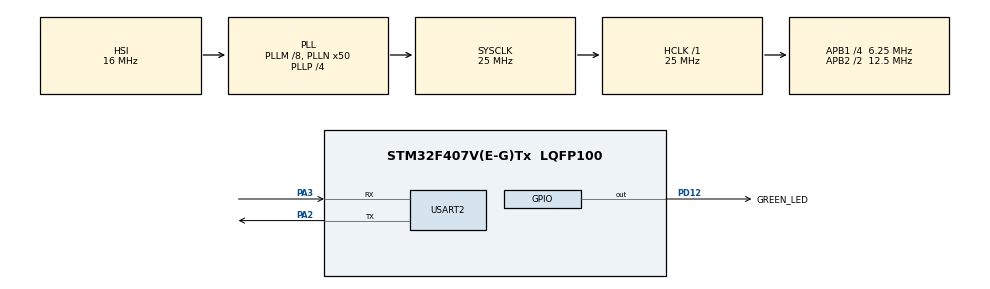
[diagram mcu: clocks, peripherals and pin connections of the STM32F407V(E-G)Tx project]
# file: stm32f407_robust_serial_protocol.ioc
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Mcu.Family=STM32F4
Mcu.Name=STM32F407V(E-G)Tx
Mcu.Package=LQFP100
NVIC.PriorityGroup=NVIC_PRIORITYGROUP_0
NVIC.USART2_IRQn=true\:0\:0\:false\:false\:true\:true\:true\:true
PA2.Mode=Asynchronous
PA2.Signal=USART2_TX
PA3.Mode=Asynchronous
PA3.Signal=USART2_RX
PD12.GPIO_Label=GREEN_LED
PD12.Signal=GPIO_Output
ProjectManager.HeapSize=0x200
ProjectManager.StackSize=0x400
ProjectManager.TargetToolchain=STM32CubeIDE
RCC.48MHZClocksFreq_Value=14285714.285714285
RCC.AHBFreq_Value=25000000
RCC.APB1CLKDivider=RCC_HCLK_DIV4
RCC.APB1Freq_Value=6250000
RCC.APB1TimFreq_Value=12500000
RCC.APB2CLKDivider=RCC_HCLK_DIV2
RCC.APB2Freq_Value=12500000
RCC.APB2TimFreq_Value=25000000
RCC.CortexFreq_Value=25000000
RCC.HCLKFreq_Value=25000000
RCC.HSE_VALUE=8000000
RCC.HSI_VALUE=16000000
RCC.LSE_VALUE=32768
RCC.PLLM=8
RCC.PLLN=50
RCC.PLLP=RCC_PLLP_DIV4
RCC.PLLQ=7
RCC.SYSCLKFreq_VALUE=25000000
RCC.SYSCLKSource=RCC_SYSCLKSOURCE_PLLCLK
RCC.VCOOutputFreq_Value=100000000
USART2.VirtualMode=VM_ASYNC
board=STM32F407G-DISC1

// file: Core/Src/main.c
/* USER CODE BEGIN Header */
/**
  ******************************************************************************
  * @file           : main.c
  * @brief          : Main program body
  ******************************************************************************
  * @attention
  *
  * Copyright (c) 2026 STMicroelectronics.
  * All rights reserved.
  *
  * This software is licensed under terms that can be found in the LICENSE file
  * in the root directory of this software component.
  * If no LICENSE file comes with this software, it is provided AS-IS.
  *
  ******************************************************************************
  */
/* USER CODE END Header */
#include "main.h"
#include "usart.h"
#include "gpio.h"

/* USER CODE BEGIN Includes */

#include <stdio.h>
#include <stdbool.h>
#include <string.h>
/* USER CODE END Includes */

/* USER CODE BEGIN PTD */

typedef enum
{
    PROTOCOL_CMD_PING          = 0x01U,
    PROTOCOL_CMD_GET_VERSION   = 0x02U,
    PROTOCOL_CMD_SET_LED       = 0x03U,
    PROTOCOL_CMD_GET_LED       = 0x04U,
    PROTOCOL_CMD_RESET_COUNTER = 0x05U
} ProtocolCommand_t;

typedef enum
{
    PROTOCOL_RESP_PONG          = 0x81U,
    PROTOCOL_RESP_VERSION       = 0x82U,
    PROTOCOL_RESP_LED_SET       = 0x83U,
    PROTOCOL_RESP_LED_STATE     = 0x84U,
    PROTOCOL_RESP_COUNTER_RESET = 0x85U,
    PROTOCOL_RESP_ERROR         = 0xFFU
} ProtocolResponse_t;

typedef enum
{
    PROTOCOL_ERROR_UNKNOWN_COMMAND = 0x01U,
    PROTOCOL_ERROR_INVALID_LENGTH  = 0x02U,
    PROTOCOL_ERROR_INVALID_PAYLOAD = 0x03U,
    PROTOCOL_ERROR_BAD_CHECKSUM    = 0x04U,
    PROTOCOL_ERROR_RX_TIMEOUT      = 0x05U,
    PROTOCOL_ERROR_BUFFER_OVERFLOW = 0x06U
} ProtocolError_t;

typedef enum
{
    PARSER_WAIT_START = 0,
    PARSER_READ_COMMAND,
    PARSER_READ_LENGTH,
    PARSER_READ_PAYLOAD,
    PARSER_READ_CHECKSUM
} ProtocolParserState_t;

typedef enum
{
    UART_RX_MODE_TEXT = 0,
    UART_RX_MODE_BINARY
} UartRxMode_t;

/* USER CODE END PTD */

/* USER CODE BEGIN PD */

#define RX_BUFFER_SIZE 				32U

#define PROTOCOL_START_BYTE        0xAAU
#define PROTOCOL_MAX_PAYLOAD_SIZE  16U

/* USER CODE END PD */

/* USER CODE BEGIN PV */

typedef struct
{
    uint8_t command;
    uint8_t length;
    uint8_t payload[PROTOCOL_MAX_PAYLOAD_SIZE];
    uint8_t checksum;
} ProtocolPacket_t;

static ProtocolPacket_t completed_packet;

static volatile bool completed_packet_ready = false;
static volatile bool bad_checksum_pending = false;

uint8_t uart_rx_byte;
uint8_t rx_buffer[RX_BUFFER_SIZE];

volatile uint8_t rx_index = 0U;
volatile uint8_t line_ready = 0U;
volatile uint8_t discard_until_newline = 0U;
volatile uint8_t rx_overflow = 0U;
volatile uint8_t rx_rearm_error = 0U;

static uint8_t green_led_state = 0U;

static ProtocolParserState_t parser_state = PARSER_WAIT_START;
static uint8_t parser_command = 0U;

static uint8_t parser_length = 0U;
static uint8_t parser_payload_index = 0U;

static uint8_t parser_payload[PROTOCOL_MAX_PAYLOAD_SIZE];

static uint8_t parser_received_checksum = 0U;
static uint8_t parser_calculated_checksum = 0U;

static bool parser_packet_complete = false;
static bool parser_packet_valid = false;

static volatile UartRxMode_t uart_rx_mode = UART_RX_MODE_TEXT;

/* USER CODE END PV */

void SystemClock_Config(void);
/* USER CODE BEGIN PFP */

static void uart_send_text(const char *text);
static void process_command(const char *command);

static uint8_t protocol_calculate_checksum(
    uint8_t command,
    uint8_t length,
    const uint8_t *payload
);

static bool protocol_checksum_self_test(void);

static void protocol_parser_reset(void);

static void protocol_parser_process_byte(uint8_t byte);

static bool protocol_parser_stage1_self_test(void);

static bool protocol_parser_stage2_self_test(void);

static bool protocol_parser_stage4_self_test(void);

static void protocol_publish_valid_packet(void);

static bool protocol_parser_stage5_self_test(void);

/* USER CODE END PFP */

/* USER CODE BEGIN 0 */

static void uart_send_text(const char *text)
{
    HAL_UART_Transmit(
        &huart2,
        (uint8_t *)text,
        strlen(text),
        HAL_MAX_DELAY
    );
}

static void process_command(const char *command)
{
    static const char set_led_prefix[] = "SET_LED ";
    const size_t set_led_prefix_length = sizeof(set_led_prefix) - 1U;

    if (strcmp(command, "PING") == 0)
    {
        uart_send_text("PONG\r\n");
    }
    else if (strcmp(command, "GET_VERSION") == 0)
    {
        uart_send_text("VERSION:1.0.0\r\n");
    }
    else if (strcmp(command, "GET_LED") == 0)
    {
        if (green_led_state == 1U)
        {
            uart_send_text("LED:1\r\n");
        }
        else
        {
            uart_send_text("LED:0\r\n");
        }
    }
    else if (strncmp(
                 command,
                 set_led_prefix,
                 set_led_prefix_length
             ) == 0)
    {
        const char *payload = command + set_led_prefix_length;

        if (strcmp(payload, "1") == 0)
        {
            HAL_GPIO_WritePin(
                GREEN_LED_GPIO_Port,
                GREEN_LED_Pin,
                GPIO_PIN_SET
            );

            green_led_state = 1U;
            uart_send_text("OK:LED_ON\r\n");
        }
        else if (strcmp(payload, "0") == 0)
        {
            HAL_GPIO_WritePin(
                GREEN_LED_GPIO_Port,
                GREEN_LED_Pin,
                GPIO_PIN_RESET
            );

            green_led_state = 0U;
            uart_send_text("OK:LED_OFF\r\n");
        }
        else
        {
            uart_send_text("ERR:INVALID_PAYLOAD\r\n");
        }
    }
    else if (strcmp(command, "SET_LED") == 0)
    {
        uart_send_text("ERR:INVALID_PAYLOAD\r\n");
    }
    else
    {
        uart_send_text("ERR:UNKNOWN_COMMAND\r\n");
    }
}

static uint8_t protocol_calculate_checksum(
    uint8_t command,
    uint8_t length,
    const uint8_t *payload
)
{
    uint8_t checksum = command ^ length;

    for (uint8_t index = 0U; index < length; index++)
    {
        checksum ^= payload[index];
    }

    return checksum;
}

static bool protocol_checksum_self_test(void)
{
    const uint8_t led_on_payload[] = {1U};
    const uint8_t led_off_payload[] = {0U};

    const uint8_t ping_checksum =
        protocol_calculate_checksum(
            PROTOCOL_CMD_PING,
            0U,
            NULL
        );

    const uint8_t led_on_checksum =
        protocol_calculate_checksum(
            PROTOCOL_CMD_SET_LED,
            1U,
            led_on_payload
        );

    const uint8_t led_off_checksum =
        protocol_calculate_checksum(
            PROTOCOL_CMD_SET_LED,
            1U,
            led_off_payload
        );

    if (ping_checksum != 0x01U)
    {
        return false;
    }

    if (led_on_checksum != 0x03U)
    {
        return false;
    }

    if (led_off_checksum != 0x02U)
    {
        return false;
    }

    return true;
}

static void protocol_parser_reset(void)
{
    parser_state = PARSER_WAIT_START;
    parser_command = 0U;
    parser_length = 0U;
    parser_payload_index = 0U;
}

static void protocol_parser_process_byte(uint8_t byte)
{
    switch (parser_state)
    {

    case PARSER_WAIT_START:

        if (byte == PROTOCOL_START_BYTE)
        {
            parser_command = 0U;
            parser_length = 0U;
            parser_payload_index = 0U;

            parser_received_checksum = 0U;
            parser_calculated_checksum = 0U;

            parser_packet_complete = false;
            parser_packet_valid = false;

            parser_state = PARSER_READ_COMMAND;
        }

        break;

        case PARSER_READ_COMMAND:

            parser_command = byte;
            parser_state = PARSER_READ_LENGTH;

            break;

        case PARSER_READ_LENGTH:

            parser_length = byte;
            parser_payload_index = 0U;

            if (parser_length > PROTOCOL_MAX_PAYLOAD_SIZE)
            {
                protocol_parser_reset();
            }
            else if (parser_length == 0U)
            {
                parser_state = PARSER_READ_CHECKSUM;
            }
            else
            {
                parser_state = PARSER_READ_PAYLOAD;
            }

            break;

        case PARSER_READ_PAYLOAD:

            parser_payload[parser_payload_index] = byte;
            parser_payload_index++;

            if (parser_payload_index >= parser_length)
            {
                parser_state = PARSER_READ_CHECKSUM;
            }

            break;

        case PARSER_READ_CHECKSUM:

            parser_received_checksum = byte;

            parser_calculated_checksum =
                protocol_calculate_checksum(
                    parser_command,
                    parser_length,
                    parser_payload
                );

            parser_packet_complete = true;

            if (parser_received_checksum == parser_calculated_checksum)
            {
                parser_packet_valid = true;
                protocol_publish_valid_packet();
            }
            else
            {
                parser_packet_valid = false;
                bad_checksum_pending = true;
            }

            parser_state = PARSER_WAIT_START;

            break;

        default:

            protocol_parser_reset();

            break;
    }
}

static bool protocol_parser_stage1_self_test(void)
{
    protocol_parser_reset();

    protocol_parser_process_byte(0x55U);

    if (parser_state != PARSER_WAIT_START)
    {
        protocol_parser_reset();
        return false;
    }

    protocol_parser_process_byte(PROTOCOL_START_BYTE);

    if (parser_state != PARSER_READ_COMMAND)
    {
        protocol_parser_reset();
        return false;
    }

    protocol_parser_process_byte(PROTOCOL_CMD_SET_LED);

    if (parser_command != PROTOCOL_CMD_SET_LED)
    {
        protocol_parser_reset();
        return false;
    }

    if (parser_state != PARSER_READ_LENGTH)
    {
        protocol_parser_reset();
        return false;
    }

    protocol_parser_reset();

    return true;
}

static bool protocol_parser_stage2_self_test(void)
{
    /*
     * Test 1:
     * PING has zero payload bytes.
     * Parser must continue directly to checksum.
     */
    protocol_parser_reset();

    protocol_parser_process_byte(PROTOCOL_START_BYTE);
    protocol_parser_process_byte(PROTOCOL_CMD_PING);
    protocol_parser_process_byte(0U);

    if (parser_length != 0U)
    {
        protocol_parser_reset();
        return false;
    }

    if (parser_state != PARSER_READ_CHECKSUM)
    {
        protocol_parser_reset();
        return false;
    }

    /*
     * Test 2:
     * SET_LED has one payload byte.
     * Parser must continue to payload state.
     */
    protocol_parser_reset();

    protocol_parser_process_byte(PROTOCOL_START_BYTE);
    protocol_parser_process_byte(PROTOCOL_CMD_SET_LED);
    protocol_parser_process_byte(1U);

    if (parser_length != 1U)
    {
        protocol_parser_reset();
        return false;
    }

    if (parser_state != PARSER_READ_PAYLOAD)
    {
        protocol_parser_reset();
        return false;
    }

    /*
     * Test 3:
     * Reject lengths larger than the maximum payload size.
     */
    protocol_parser_reset();

    protocol_parser_process_byte(PROTOCOL_START_BYTE);
    protocol_parser_process_byte(PROTOCOL_CMD_SET_LED);
    protocol_parser_process_byte(PROTOCOL_MAX_PAYLOAD_SIZE + 1U);

    if (parser_state != PARSER_WAIT_START)
    {
        protocol_parser_reset();
        return false;
    }

    protocol_parser_reset();

    return true;
}

static bool protocol_parser_stage3_self_test(void)
{
    /*
     * Test 1:
     * SET_LED packet with one payload byte.
     */
    protocol_parser_reset();

    protocol_parser_process_byte(PROTOCOL_START_BYTE);
    protocol_parser_process_byte(PROTOCOL_CMD_SET_LED);
    protocol_parser_process_byte(1U);
    protocol_parser_process_byte(1U);

    if (parser_payload_index != 1U)
    {
        protocol_parser_reset();
        return false;
    }

    if (parser_payload[0] != 1U)
    {
        protocol_parser_reset();
        return false;
    }

    if (parser_state != PARSER_READ_CHECKSUM)
    {
        protocol_parser_reset();
        return false;
    }

    /*
     * Test 2:
     * Generic command with three payload bytes.
     */
    protocol_parser_reset();

    protocol_parser_process_byte(PROTOCOL_START_BYTE);
    protocol_parser_process_byte(0x06U);
    protocol_parser_process_byte(3U);

    protocol_parser_process_byte(1U);

    if (parser_payload_index != 1U)
    {
        protocol_parser_reset();
        return false;
    }

    if (parser_state != PARSER_READ_PAYLOAD)
    {
        protocol_parser_reset();
        return false;
    }

    protocol_parser_process_byte(0U);

    if (parser_payload_index != 2U)
    {
        protocol_parser_reset();
        return false;
    }

    if (parser_state != PARSER_READ_PAYLOAD)
    {
        protocol_parser_reset();
        return false;
    }

    protocol_parser_process_byte(1U);

    if (parser_payload_index != 3U)
    {
        protocol_parser_reset();
        return false;
    }

    if ((parser_payload[0] != 1U) ||
        (parser_payload[1] != 0U) ||
        (parser_payload[2] != 1U))
    {
        protocol_parser_reset();
        return false;
    }

    if (parser_state != PARSER_READ_CHECKSUM)
    {
        protocol_parser_reset();
        return false;
    }

    protocol_parser_reset();

    return true;
}

static bool protocol_parser_stage4_self_test(void)
{
    /*
     * Test 1:
     * Valid SET_LED ON packet.
     * AA 03 01 01 03
     */
    protocol_parser_reset();

    protocol_parser_process_byte(PROTOCOL_START_BYTE);
    protocol_parser_process_byte(PROTOCOL_CMD_SET_LED);
    protocol_parser_process_byte(1U);
    protocol_parser_process_byte(1U);
    protocol_parser_process_byte(0x03U);

    if (parser_packet_complete == false)
    {
        protocol_parser_reset();
        return false;
    }

    if (parser_packet_valid == false)
    {
        protocol_parser_reset();
        return false;
    }

    if (parser_received_checksum != 0x03U)
    {
        protocol_parser_reset();
        return false;
    }

    if (parser_calculated_checksum != 0x03U)
    {
        protocol_parser_reset();
        return false;
    }

    if (parser_state != PARSER_WAIT_START)
    {
        protocol_parser_reset();
        return false;
    }

    /*
     * Test 2:
     * Invalid SET_LED ON packet.
     * Correct checksum should be 0x03,
     * but received checksum is 0x00.
     */
    protocol_parser_reset();

    protocol_parser_process_byte(PROTOCOL_START_BYTE);
    protocol_parser_process_byte(PROTOCOL_CMD_SET_LED);
    protocol_parser_process_byte(1U);
    protocol_parser_process_byte(1U);
    protocol_parser_process_byte(0x00U);

    if (parser_packet_complete == false)
    {
        protocol_parser_reset();
        return false;
    }

    if (parser_packet_valid == true)
    {
        protocol_parser_reset();
        return false;
    }

    if (parser_received_checksum != 0x00U)
    {
        protocol_parser_reset();
        return false;
    }

    if (parser_calculated_checksum != 0x03U)
    {
        protocol_parser_reset();
        return false;
    }

    /*
     * Test 3:
     * Valid PING packet with no payload.
     * AA 01 00 01
     */
    protocol_parser_reset();

    protocol_parser_process_byte(PROTOCOL_START_BYTE);
    protocol_parser_process_byte(PROTOCOL_CMD_PING);
    protocol_parser_process_byte(0U);
    protocol_parser_process_byte(0x01U);

    if ((parser_packet_complete == false) ||
        (parser_packet_valid == false))
    {
        protocol_parser_reset();
        return false;
    }

    if (parser_calculated_checksum != 0x01U)
    {
        protocol_parser_reset();
        return false;
    }

    protocol_parser_reset();

    return true;
}

static void protocol_publish_valid_packet(void)
{
    completed_packet.command = parser_command;
    completed_packet.length = parser_length;
    completed_packet.checksum = parser_received_checksum;

    for (uint8_t index = 0U; index < parser_length; index++)
    {
        completed_packet.payload[index] = parser_payload[index];
    }

    completed_packet_ready = true;
}

static bool protocol_parser_stage5_self_test(void)
{
    /*
     * Test 1:
     * A valid SET_LED ON packet must be copied
     * into completed_packet.
     */
    protocol_parser_reset();

    completed_packet_ready = false;
    bad_checksum_pending = false;

    protocol_parser_process_byte(PROTOCOL_START_BYTE);
    protocol_parser_process_byte(PROTOCOL_CMD_SET_LED);
    protocol_parser_process_byte(1U);
    protocol_parser_process_byte(1U);
    protocol_parser_process_byte(0x03U);

    if (completed_packet_ready == false)
    {
        protocol_parser_reset();
        return false;
    }

    if (bad_checksum_pending == true)
    {
        protocol_parser_reset();
        return false;
    }

    if (completed_packet.command != PROTOCOL_CMD_SET_LED)
    {
        protocol_parser_reset();
        return false;
    }

    if (completed_packet.length != 1U)
    {
        protocol_parser_reset();
        return false;
    }

    if (completed_packet.payload[0] != 1U)
    {
        protocol_parser_reset();
        return false;
    }

    if (completed_packet.checksum != 0x03U)
    {
        protocol_parser_reset();
        return false;
    }

    /*
     * Simulate that the main loop consumed the packet.
     */
    completed_packet_ready = false;

    /*
     * Test 2:
     * A packet with a bad checksum must not be published.
     */
    bad_checksum_pending = false;

    protocol_parser_reset();

    protocol_parser_process_byte(PROTOCOL_START_BYTE);
    protocol_parser_process_byte(PROTOCOL_CMD_SET_LED);
    protocol_parser_process_byte(1U);
    protocol_parser_process_byte(1U);
    protocol_parser_process_byte(0x00U);

    if (completed_packet_ready == true)
    {
        protocol_parser_reset();
        return false;
    }

    if (bad_checksum_pending == false)
    {
        protocol_parser_reset();
        return false;
    }

    /*
     * Restore clean runtime state after the self-test.
     */
    completed_packet_ready = false;
    bad_checksum_pending = false;

    protocol_parser_reset();

    return true;
}

/* USER CODE END 0 */

int main(void)
{

  /* MCU Configuration--------------------------------------------------------*/

  /* Reset of all peripherals, Initializes the Flash interface and the Systick. */
  HAL_Init();

  /* Configure the system clock */
  SystemClock_Config();

  /* Initialize all configured peripherals */
  MX_GPIO_Init();
  MX_USART2_UART_Init();
  /* USER CODE BEGIN 2 */

  const uint8_t boot_msg[] = "BOOT_OK\r\n";

  HAL_UART_Transmit(&huart2, (uint8_t* )boot_msg, sizeof(boot_msg) - 1U, HAL_MAX_DELAY);

  if (protocol_checksum_self_test())
  {
      uart_send_text("CHECKSUM_TEST:PASS\r\n");
  }
  else
  {
      uart_send_text("CHECKSUM_TEST:FAIL\r\n");
  }

  if (protocol_parser_stage1_self_test())
  {
      uart_send_text("PARSER_STAGE1_TEST:PASS\r\n");
  }
  else
  {
      uart_send_text("PARSER_STAGE1_TEST:FAIL\r\n");
  }

  if (protocol_parser_stage2_self_test())
  {
      uart_send_text("PARSER_STAGE2_TEST:PASS\r\n");
  }
  else
  {
      uart_send_text("PARSER_STAGE2_TEST:FAIL\r\n");
  }

  if (protocol_parser_stage3_self_test())
  {
      uart_send_text("PARSER_STAGE3_TEST:PASS\r\n");
  }
  else
  {
      uart_send_text("PARSER_STAGE3_TEST:FAIL\r\n");
  }

  if (protocol_parser_stage4_self_test())
  {
      uart_send_text("PARSER_STAGE4_TEST:PASS\r\n");
  }
  else
  {
      uart_send_text("PARSER_STAGE4_TEST:FAIL\r\n");
  }

  if (protocol_parser_stage5_self_test())
  {
      uart_send_text("PARSER_STAGE5_TEST:PASS\r\n");
  }
  else
  {
      uart_send_text("PARSER_STAGE5_TEST:FAIL\r\n");
  }

  if (HAL_UART_Receive_IT(&huart2, &uart_rx_byte, 1U) != HAL_OK)
  {
	  Error_Handler();
  }

  /* USER CODE END 2 */

  /* Infinite loop */
  while (1)
  {

    /* USER CODE BEGIN 3 */
	  if (line_ready == 1U)
	  {
	      process_command((char *)rx_buffer);

	      rx_index = 0U;
	      line_ready = 0U;
	  }

	  if (rx_overflow == 1U)
	  {
	      uart_send_text("ERR:RX_OVERFLOW\r\n");
	      rx_overflow = 0U;
	  }

	  if (rx_rearm_error == 1U)
	  {
	      Error_Handler();
	  }

	  if (completed_packet_ready == true)
	  {
	      if ((completed_packet.command == PROTOCOL_CMD_PING) &&
	          (completed_packet.length == 0U))
	      {
	          uart_send_text("BIN:PONG\r\n");
	      }
	      else
	      {
	          uart_send_text("BIN:PACKET_OK\r\n");
	      }

	      completed_packet_ready = false;
	  }

	  if (bad_checksum_pending == true)
	  {
	      uart_send_text("BIN:BAD_CHECKSUM\r\n");
	      bad_checksum_pending = false;
	  }
  }
  /* USER CODE END 3 */
}

void SystemClock_Config(void)
{
  RCC_OscInitTypeDef RCC_OscInitStruct = {0};
  RCC_ClkInitTypeDef RCC_ClkInitStruct = {0};

  /** Configure the main internal regulator output voltage
  */
  __HAL_RCC_PWR_CLK_ENABLE();
  __HAL_PWR_VOLTAGESCALING_CONFIG(PWR_REGULATOR_VOLTAGE_SCALE1);

  /** Initializes the RCC Oscillators according to the specified parameters
  * in the RCC_OscInitTypeDef structure.
  */
  RCC_OscInitStruct.OscillatorType = RCC_OSCILLATORTYPE_HSI;
  RCC_OscInitStruct.HSIState = RCC_HSI_ON;
  RCC_OscInitStruct.HSICalibrationValue = RCC_HSICALIBRATION_DEFAULT;
  RCC_OscInitStruct.PLL.PLLState = RCC_PLL_ON;
  RCC_OscInitStruct.PLL.PLLSource = RCC_PLLSOURCE_HSI;
  RCC_OscInitStruct.PLL.PLLM = 8;
  RCC_OscInitStruct.PLL.PLLN = 50;
  RCC_OscInitStruct.PLL.PLLP = RCC_PLLP_DIV4;
  RCC_OscInitStruct.PLL.PLLQ = 7;
  if (HAL_RCC_OscConfig(&RCC_OscInitStruct) != HAL_OK)
  {
    Error_Handler();
  }

  /** Initializes the CPU, AHB and APB buses clocks
  */
  RCC_ClkInitStruct.ClockType = RCC_CLOCKTYPE_HCLK|RCC_CLOCKTYPE_SYSCLK
                              |RCC_CLOCKTYPE_PCLK1|RCC_CLOCKTYPE_PCLK2;
  RCC_ClkInitStruct.SYSCLKSource = RCC_SYSCLKSOURCE_PLLCLK;
  RCC_ClkInitStruct.AHBCLKDivider = RCC_SYSCLK_DIV1;
  RCC_ClkInitStruct.APB1CLKDivider = RCC_HCLK_DIV4;
  RCC_ClkInitStruct.APB2CLKDivider = RCC_HCLK_DIV2;

  if (HAL_RCC_ClockConfig(&RCC_ClkInitStruct, FLASH_LATENCY_0) != HAL_OK)
  {
    Error_Handler();
  }
}

/* USER CODE BEGIN 4 */

void HAL_UART_RxCpltCallback(UART_HandleTypeDef *huart)
{
    if (huart->Instance == USART2)
    {
    	if ((uart_rx_mode == UART_RX_MODE_BINARY) ||
    	    (uart_rx_byte == PROTOCOL_START_BYTE))
    	{
    	    if (uart_rx_mode == UART_RX_MODE_TEXT)
    	    {
    	        protocol_parser_reset();
    	        uart_rx_mode = UART_RX_MODE_BINARY;
    	    }

    	    protocol_parser_process_byte(uart_rx_byte);

    	    if (parser_state == PARSER_WAIT_START)
    	    {
    	        uart_rx_mode = UART_RX_MODE_TEXT;
    	    }
    	}
    	else
    	{
    	    /*
    	     * Existing text command reception code.
    	     */
    	    if (line_ready == 0U)
    	    {
    	        if ((uart_rx_byte == '\r') || (uart_rx_byte == '\n'))
    	        {
    	            if (discard_until_newline == 1U)
    	            {
    	                discard_until_newline = 0U;
    	                rx_index = 0U;
    	                rx_overflow = 1U;
    	            }
    	            else if (rx_index > 0U)
    	            {
    	                rx_buffer[rx_index] = '\0';
    	                line_ready = 1U;
    	            }
    	        }
    	        else if (discard_until_newline == 0U)
    	        {
    	            if (rx_index < (RX_BUFFER_SIZE - 1U))
    	            {
    	                rx_buffer[rx_index] = uart_rx_byte;
    	                rx_index++;
    	            }
    	            else
    	            {
    	                discard_until_newline = 1U;
    	            }
    	        }
    	    }
    	}

        if (HAL_UART_Receive_IT(&huart2, &uart_rx_byte, 1U) != HAL_OK)
        {
            rx_rearm_error = 1U;
        }
    }
}
/* USER CODE END 4 */

void Error_Handler(void)
{
  __disable_irq();
  while (1)
  {
  }
}
